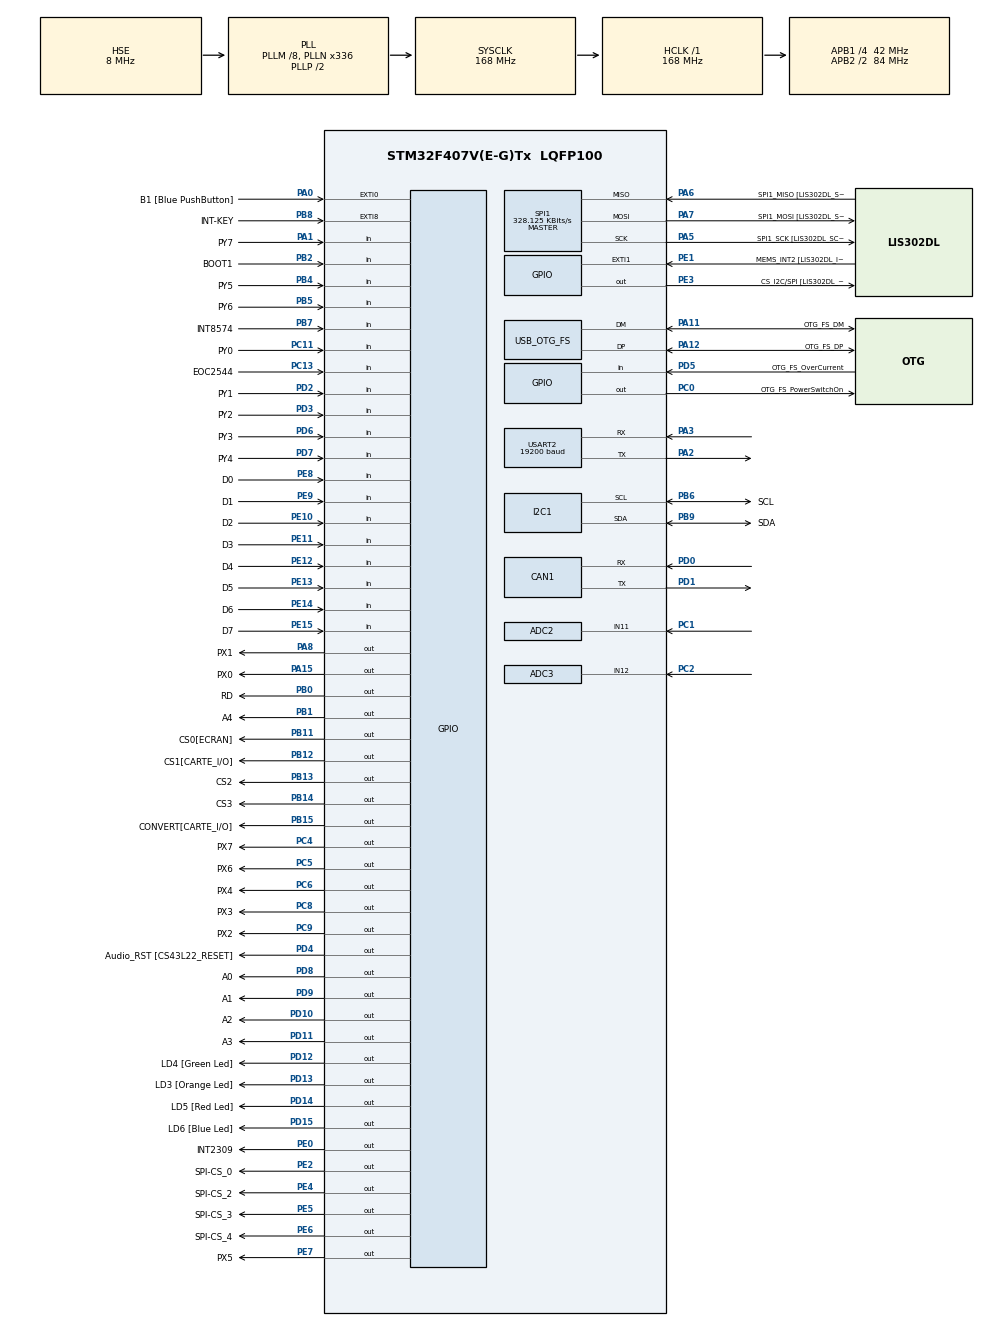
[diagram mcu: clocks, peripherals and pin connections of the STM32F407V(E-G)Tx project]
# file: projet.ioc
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ADC1.Channel-0\#ChannelRegularConversion=ADC_CHANNEL_TEMPSENSOR
ADC1.ExternalTrigConv=ADC_EXTERNALTRIGCONV_T1_CC1
ADC1.NbrOfConversionFlag=1
ADC1.Rank-0\#ChannelRegularConversion=1
ADC1.SamplingTime-0\#ChannelRegularConversion=ADC_SAMPLETIME_3CYCLES
ADC1.master=1
ADC2.Channel-0\#ChannelRegularConversion=ADC_CHANNEL_11
ADC2.ExternalTrigConv=ADC_EXTERNALTRIGCONV_T1_CC1
ADC2.NbrOfConversionFlag=1
ADC2.Rank-0\#ChannelRegularConversion=1
ADC2.SamplingTime-0\#ChannelRegularConversion=ADC_SAMPLETIME_3CYCLES
ADC3.Channel-0\#ChannelRegularConversion=ADC_CHANNEL_12
ADC3.ExternalTrigConv=ADC_EXTERNALTRIGCONV_T1_CC1
ADC3.NbrOfConversionFlag=1
ADC3.Rank-0\#ChannelRegularConversion=1
ADC3.SamplingTime-0\#ChannelRegularConversion=ADC_SAMPLETIME_3CYCLES
CAN1.CalculateTimeBit=1142
CAN1.CalculateTimeQuantum=380.95238095238096
Mcu.Family=STM32F4
Mcu.Name=STM32F407V(E-G)Tx
Mcu.Package=LQFP100
NVIC.EXTI9_5_IRQn=true\:0\:0\:false\:false\:true
NVIC.OTG_FS_IRQn=true\:0\:0\:false\:false\:true
NVIC.PriorityGroup=NVIC_PRIORITYGROUP_0
PA0-WKUP.GPIO_Label=B1 [Blue PushButton]
PA0-WKUP.GPIO_ModeDefaultEXTI=GPIO_MODE_EVT_RISING
PA0-WKUP.GPIO_PuPd=GPIO_NOPULL
PA0-WKUP.Signal=GPXTI0
PA1.GPIO_Label=PY7
PA1.Signal=GPIO_Input
PA10.GPIO_Label=OTG_FS_ID
PA10.GPIO_Mode=GPIO_MODE_AF_PP
PA10.GPIO_PuPd=GPIO_NOPULL
PA10.GPIO_Speed=GPIO_SPEED_FREQ_LOW
PA10.Signal=USB_OTG_FS_ID
PA11.GPIO_Label=OTG_FS_DM
PA11.GPIO_Mode=GPIO_MODE_AF_PP
PA11.GPIO_PuPd=GPIO_NOPULL
PA11.GPIO_Speed=GPIO_SPEED_FREQ_LOW
PA11.Mode=Device_Only
PA11.Signal=USB_OTG_FS_DM
PA12.GPIO_Label=OTG_FS_DP
PA12.GPIO_Mode=GPIO_MODE_AF_PP
PA12.GPIO_PuPd=GPIO_NOPULL
PA12.GPIO_Speed=GPIO_SPEED_FREQ_LOW
PA12.Mode=Device_Only
PA12.Signal=USB_OTG_FS_DP
PA13.GPIO_Label=SWDIO
PA13.Mode=Trace_Asynchronous_SW
PA13.Signal=SYS_JTMS-SWDIO
PA14.GPIO_Label=SWCLK
PA14.Mode=Trace_Asynchronous_SW
PA14.Signal=SYS_JTCK-SWCLK
PA15.GPIO_Label=PX0
PA15.Signal=GPIO_Output
PA2.Mode=Asynchronous
PA2.Signal=USART2_TX
PA3.Mode=Asynchronous
PA3.Signal=USART2_RX
PA4.GPIO_Label=I2S3_WS [CS43L22_LRCK]
PA4.GPIO_Mode=GPIO_MODE_AF_PP
PA4.GPIO_PuPd=GPIO_NOPULL
PA4.GPIO_Speed=GPIO_SPEED_FREQ_LOW
PA4.Signal=I2S3_WS
PA5.GPIO_Label=SPI1_SCK [LIS302DL_SCL/SPC]
PA5.GPIO_Mode=GPIO_MODE_AF_PP
PA5.GPIO_PuPd=GPIO_NOPULL
PA5.GPIO_Speed=GPIO_SPEED_FREQ_LOW
PA5.Mode=Full_Duplex_Master
PA5.Signal=SPI1_SCK
PA6.GPIO_Label=SPI1_MISO [LIS302DL_SDO]
PA6.GPIO_Mode=GPIO_MODE_AF_PP
PA6.GPIO_PuPd=GPIO_NOPULL
PA6.GPIO_Speed=GPIO_SPEED_FREQ_LOW
PA6.Mode=Full_Duplex_Master
PA6.Signal=SPI1_MISO
PA7.GPIO_Label=SPI1_MOSI [LIS302DL_SDA/SDI/SDO]
PA7.GPIO_Mode=GPIO_MODE_AF_PP
PA7.GPIO_PuPd=GPIO_NOPULL
PA7.GPIO_Speed=GPIO_SPEED_FREQ_LOW
PA7.Mode=Full_Duplex_Master
PA7.Signal=SPI1_MOSI
PA8.GPIO_Label=PX1
PA8.Signal=GPIO_Output
PA9.GPIO_Label=VBUS_FS
PA9.GPIO_Mode=GPIO_MODE_INPUT
PA9.GPIO_PuPd=GPIO_NOPULL
PA9.Signal=USB_OTG_FS_VBUS
PB0.GPIO_Label=RD
PB0.Signal=GPIO_Output
PB1.GPIO_Label=A4
PB1.Signal=GPIO_Output
PB10.GPIO_Label=CLK_IN [MP45DT02_CLK]
PB10.GPIO_Mode=GPIO_MODE_AF_PP
PB10.GPIO_PuPd=GPIO_NOPULL
PB10.GPIO_Speed=GPIO_SPEED_FREQ_LOW
PB10.Signal=I2S2_CK
PB11.GPIO_Label=CS0[ECRAN]
PB11.Signal=GPIO_Output
PB12.GPIO_Label=CS1[CARTE_I/O]
PB12.Signal=GPIO_Output
PB13.GPIO_Label=CS2
PB13.Signal=GPIO_Output
PB14.GPIO_Label=CS3
PB14.Signal=GPIO_Output
PB15.GPIO_Label=CONVERT[CARTE_I/O]
PB15.Signal=GPIO_Output
PB2.GPIO_Label=BOOT1
PB2.GPIO_Mode=GPIO_MODE_INPUT
PB2.GPIO_PuPd=GPIO_NOPULL
PB2.Signal=GPIO_Input
PB3.GPIO_Label=SWO
PB3.Mode=Trace_Asynchronous_SW
PB3.Signal=SYS_JTDO-SWO
PB4.GPIO_Label=PY5
PB4.Signal=GPIO_Input
PB5.GPIO_Label=PY6
PB5.Signal=GPIO_Input
PB6.GPIO_Label=SCL
PB6.GPIO_Mode=GPIO_MODE_AF_OD
PB6.GPIO_PuPd=GPIO_NOPULL
PB6.GPIO_Speed=GPIO_SPEED_FREQ_LOW
PB6.Mode=I2C
PB6.Signal=I2C1_SCL
PB7.GPIO_Label=INT8574
PB7.Signal=GPIO_Input
PB8.GPIO_Label=INT-KEY
PB8.Signal=GPXTI8
PB9.GPIO_Label=SDA
PB9.GPIO_Mode=GPIO_MODE_AF_OD
PB9.GPIO_PuPd=GPIO_NOPULL
PB9.GPIO_Speed=GPIO_SPEED_FREQ_LOW
PB9.Mode=I2C
PB9.Signal=I2C1_SDA
PC0.GPIO_Label=OTG_FS_PowerSwitchOn
PC0.GPIO_PuPd=GPIO_NOPULL
PC0.GPIO_Speed=GPIO_SPEED_FREQ_LOW
PC0.Signal=GPIO_Output
PC1.Signal=ADCx_IN11
PC10.GPIO_Label=I2S3_SCK [CS43L22_SCLK]
PC10.GPIO_Mode=GPIO_MODE_AF_PP
PC10.GPIO_PuPd=GPIO_NOPULL
PC10.GPIO_Speed=GPIO_SPEED_FREQ_LOW
PC10.Signal=I2S3_CK
PC11.GPIO_Label=PY0
PC11.Signal=GPIO_Input
PC12.GPIO_Label=I2S3_SD [CS43L22_SDIN]
PC12.GPIO_Mode=GPIO_MODE_AF_PP
PC12.GPIO_PuPd=GPIO_NOPULL
PC12.GPIO_Speed=GPIO_SPEED_FREQ_LOW
PC12.Signal=I2S3_SD
PC13-ANTI_TAMP.GPIO_Label=EOC2544
PC13-ANTI_TAMP.Signal=GPIO_Input
PC14-OSC32_IN.GPIO_Label=PC14-OSC32_IN
PC14-OSC32_IN.Signal=RCC_OSC32_IN
PC15-OSC32_OUT.GPIO_Label=PC15-OSC32_OUT
PC15-OSC32_OUT.Signal=RCC_OSC32_OUT
PC2.Signal=ADCx_IN12
PC3.GPIO_Label=PDM_OUT [MP45DT02_DOUT]
PC3.GPIO_Mode=GPIO_MODE_AF_PP
PC3.GPIO_PuPd=GPIO_NOPULL
PC3.GPIO_Speed=GPIO_SPEED_FREQ_LOW
PC3.Signal=I2S2_SD
PC4.GPIO_Label=PX7
PC4.Signal=GPIO_Output
PC5.GPIO_Label=PX6
PC5.Signal=GPIO_Output
PC6.GPIO_Label=PX4
PC6.Signal=GPIO_Output
PC7.GPIO_Label=I2S3_MCK [CS43L22_MCLK]
PC7.GPIO_Mode=GPIO_MODE_AF_PP
PC7.GPIO_PuPd=GPIO_NOPULL
PC7.GPIO_Speed=GPIO_SPEED_FREQ_LOW
PC7.Signal=I2S3_MCK
PC8.GPIO_Label=PX3
PC8.Signal=GPIO_Output
PC9.GPIO_Label=PX2
PC9.Signal=GPIO_Output
PD0.Mode=Master
PD0.Signal=CAN1_RX
PD1.Mode=Master
PD1.Signal=CAN1_TX
PD10.GPIO_Label=A2
PD10.Signal=GPIO_Output
PD11.GPIO_Label=A3
PD11.Signal=GPIO_Output
PD12.GPIO_Label=LD4 [Green Led]
PD12.GPIO_PuPd=GPIO_NOPULL
PD12.GPIO_Speed=GPIO_SPEED_FREQ_LOW
PD12.Signal=GPIO_Output
PD13.GPIO_Label=LD3 [Orange Led]
PD13.GPIO_PuPd=GPIO_NOPULL
PD13.GPIO_Speed=GPIO_SPEED_FREQ_LOW
PD13.Signal=GPIO_Output
PD14.GPIO_Label=LD5 [Red Led]
PD14.GPIO_PuPd=GPIO_NOPULL
PD14.GPIO_Speed=GPIO_SPEED_FREQ_LOW
PD14.Signal=GPIO_Output
PD15.GPIO_Label=LD6 [Blue Led]
PD15.GPIO_PuPd=GPIO_NOPULL
PD15.GPIO_Speed=GPIO_SPEED_FREQ_LOW
PD15.Signal=GPIO_Output
PD2.GPIO_Label=PY1
PD2.Signal=GPIO_Input
PD3.GPIO_Label=PY2
PD3.Signal=GPIO_Input
PD4.GPIO_Label=Audio_RST [CS43L22_RESET]
PD4.GPIO_PuPd=GPIO_NOPULL
PD4.GPIO_Speed=GPIO_SPEED_FREQ_LOW
PD4.Signal=GPIO_Output
PD5.GPIO_Label=OTG_FS_OverCurrent
PD5.GPIO_Mode=GPIO_MODE_INPUT
PD5.GPIO_PuPd=GPIO_NOPULL
PD5.Signal=GPIO_Input
PD6.GPIO_Label=PY3
PD6.Signal=GPIO_Input
PD7.GPIO_Label=PY4
PD7.Signal=GPIO_Input
PD8.GPIO_Label=A0
PD8.Signal=GPIO_Output
PD9.GPIO_Label=A1
PD9.Signal=GPIO_Output
PE0.GPIO_Label=INT2309
PE0.Signal=GPIO_Output
PE1.GPIO_Label=MEMS_INT2 [LIS302DL_INT2]
PE1.GPIO_ModeDefaultEXTI=GPIO_MODE_EVT_RISING
PE1.GPIO_PuPd=GPIO_NOPULL
PE1.Signal=GPXTI1
PE10.GPIO_Label=D2
PE10.Signal=GPIO_Input
PE11.GPIO_Label=D3
PE11.Signal=GPIO_Input
PE12.GPIO_Label=D4
PE12.Signal=GPIO_Input
PE13.GPIO_Label=D5
PE13.Signal=GPIO_Input
PE14.GPIO_Label=D6
PE14.Signal=GPIO_Input
PE15.GPIO_Label=D7
PE15.Signal=GPIO_Input
PE2.GPIO_Label=SPI-CS_0
PE2.Signal=GPIO_Output
PE3.GPIO_Label=CS_I2C/SPI [LIS302DL_CS_I2C/SPI]
PE3.GPIO_PuPd=GPIO_NOPULL
PE3.GPIO_Speed=GPIO_SPEED_FREQ_LOW
PE3.Signal=GPIO_Output
PE4.GPIO_Label=SPI-CS_2
PE4.Signal=GPIO_Output
PE5.GPIO_Label=SPI-CS_3
PE5.Signal=GPIO_Output
PE6.GPIO_Label=SPI-CS_4
PE6.Signal=GPIO_Output
PE7.GPIO_Label=PX5
PE7.Signal=GPIO_Output
PE8.GPIO_Label=D0
PE8.Signal=GPIO_Input
PE9.GPIO_Label=D1
PE9.Signal=GPIO_Input
PH0-OSC_IN.GPIO_Label=PH0-OSC_IN
PH0-OSC_IN.Mode=HSE-External-Oscillator
PH0-OSC_IN.Signal=RCC_OSC_IN
PH1-OSC_OUT.GPIO_Label=PH1-OSC_OUT
PH1-OSC_OUT.Mode=HSE-External-Oscillator
PH1-OSC_OUT.Signal=RCC_OSC_OUT
ProjectManager.HeapSize=0x400
ProjectManager.StackSize=0x2000
ProjectManager.TargetToolchain=EWARM
RCC.AHBFreq_Value=168000000
RCC.APB1CLKDivider=RCC_HCLK_DIV4
RCC.APB1Freq_Value=42000000
RCC.APB1TimFreq_Value=84000000
RCC.APB2CLKDivider=RCC_HCLK_DIV2
RCC.APB2Freq_Value=84000000
RCC.APB2TimFreq_Value=168000000
RCC.CortexFreq_Value=168000000
RCC.HCLKFreq_Value=168000000
RCC.HSE_VALUE=8000000
RCC.HSI_VALUE=16000000
RCC.LSE_VALUE=32768
RCC.PLLM=8
RCC.PLLN=336
RCC.PLLQ=7
RCC.SYSCLKFreq_VALUE=168000000
RCC.SYSCLKSource=RCC_SYSCLKSOURCE_PLLCLK
RCC.VCOOutputFreq_Value=336000000
SH.ADCx_IN11.0=ADC2_IN11,IN11
SH.ADCx_IN12.0=ADC3_IN12,IN12
SPI1.BaudRatePrescaler=SPI_BAUDRATEPRESCALER_256
SPI1.CalculateBaudRate=328.125 KBits/s
SPI1.Mode=SPI_MODE_MASTER
USART2.BaudRate=19200
USB_DEVICE.CLASS_NAME-CDC_FS=CDC
USB_DEVICE.CLASS_NAME_FS=CDC
USB_DEVICE.USBD_HandleTypeDef-CDC_FS=hUsbDeviceFS
USB_DEVICE.VirtualMode-CDC_FS=Cdc
USB_DEVICE.VirtualModeFS=Cdc_FS
USB_OTG_FS.VirtualMode=Device_Only
VP_ADC1_TempSens_Input.Mode=IN-TempSens
VP_USB_DEVICE_VS_USB_DEVICE_CDC_FS.Mode=CDC_FS
board=STM32F4DISCOVERY

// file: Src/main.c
/**
  ******************************************************************************
  * File Name          : main.c
  * Description        : Main program body
  ******************************************************************************
  *
  * Copyright (c) 2017 STMicroelectronics International N.V.
  * All rights reserved.
  *
  * Redistribution and use in source and binary forms, with or without
  * modification, are permitted, provided that the following conditions are met:
  *
  * 1. Redistribution of source code must retain the above copyright notice,
  *    this list of conditions and the following disclaimer.
  * 2. Redistributions in binary form must reproduce the above copyright notice,
  *    this list of conditions and the following disclaimer in the documentation
  *    and/or other materials provided with the distribution.
  * 3. Neither the name of STMicroelectronics nor the names of other
  *    contributors to this software may be used to endorse or promote products
  *    derived from this software without specific written permission.
  * 4. This software, including modifications and/or derivative works of this
  *    software, must execute solely and exclusively on microcontroller or
  *    microprocessor devices manufactured by or for STMicroelectronics.
  * 5. Redistribution and use of this software other than as permitted under
  *    this license is void and will automatically terminate your rights under
  *    this license.
  *
  * THIS SOFTWARE IS PROVIDED BY STMICROELECTRONICS AND CONTRIBUTORS "AS IS"
  * AND ANY EXPRESS, IMPLIED OR STATUTORY WARRANTIES, INCLUDING, BUT NOT
  * LIMITED TO, THE IMPLIED WARRANTIES OF MERCHANTABILITY, FITNESS FOR A
  * PARTICULAR PURPOSE AND NON-INFRINGEMENT OF THIRD PARTY INTELLECTUAL PROPERTY
  * RIGHTS ARE DISCLAIMED TO THE FULLEST EXTENT PERMITTED BY LAW. IN NO EVENT
  * SHALL STMICROELECTRONICS OR CONTRIBUTORS BE LIABLE FOR ANY DIRECT, INDIRECT,
  * INCIDENTAL, SPECIAL, EXEMPLARY, OR CONSEQUENTIAL DAMAGES (INCLUDING, BUT NOT
  * LIMITED TO, PROCUREMENT OF SUBSTITUTE GOODS OR SERVICES; LOSS OF USE, DATA,
  * OR PROFITS; OR BUSINESS INTERRUPTION) HOWEVER CAUSED AND ON ANY THEORY OF
  * LIABILITY, WHETHER IN CONTRACT, STRICT LIABILITY, OR TORT (INCLUDING
  * NEGLIGENCE OR OTHERWISE) ARISING IN ANY WAY OUT OF THE USE OF THIS SOFTWARE,
  * EVEN IF ADVISED OF THE POSSIBILITY OF SUCH DAMAGE.
  *
  ******************************************************************************
  */
#include "main.h"
#include "stm32f4xx_hal.h"
#include "usb_device.h"

/* USER CODE BEGIN Includes */
#include "LIS3DSH.h"
#include "IO_BUS.h"
#include "GLcd.h"
#include "ST.h"
#include "Vehicule.h"
/* USER CODE END Includes */

ADC_HandleTypeDef hadc1;
ADC_HandleTypeDef hadc2;
ADC_HandleTypeDef hadc3;

CAN_HandleTypeDef hcan1;

I2C_HandleTypeDef hi2c1;

SPI_HandleTypeDef hspi1;

UART_HandleTypeDef huart2;

/* USER CODE BEGIN PV */
/* Private variables ---------------------------------------------------------*/

/* USER CODE END PV */

void SystemClock_Config(void);
void Error_Handler(void);
static void MX_GPIO_Init(void);
static void MX_ADC1_Init(void);
static void MX_ADC2_Init(void);
static void MX_ADC3_Init(void);
static void MX_CAN1_Init(void);
static void MX_I2C1_Init(void);
static void MX_SPI1_Init(void);
static void MX_USART2_UART_Init(void);

/* USER CODE BEGIN PFP */
/* Private function prototypes -----------------------------------------------*/

/* USER CODE END PFP */

/* USER CODE BEGIN 0 */
 uint8_t ucKey = 0x20;
/* USER CODE END 0 */

int main(void)
{

  /* USER CODE BEGIN 1 */

  uint8_t ucCode[16] = {'1','2','3','A',
                        '4','5','6','B',
                        '7','8','9','C',
                        '*','0','#','D'};

  uint8_t ucTrans[20] = {'0','0','0',0,0,' ',' ',' ',' ',' ',
                         ' ',' ',' ',' ',' ',' ',' ',' ',' ',' '};
                        // Trame Clavier
 int iRoue[4];

 unsigned char ucTrameRoue[20] = {0,0,0,0,0,0,0,0,0,0,
                                  0,0,0,0,0,0,0,0,0,0};
  // 12 (4*3) pour les roues
  // 2 pour checksum

 unsigned char ucTrameDebug[20] = {'A','V','G','A','V','D', 'A','R','G',
                                   'A','R','D'};

  unsigned char ucTableauFloat[20] = {' ',' ',' ',' ',' ',' ',' ',' ',' ',' ',
  ' ',' ',' ',' ',' ',' ',' ',' ',' ',' '};

  uint8_t ucCtrlTele = 0;  // Controle inclinometre ou clavier. Clavier = 0
                           // Inclinometre = 1.
                           // Suiveur = 2
                           // Capteur = 3.
                           // Mode clavier au demarrage.

  unsigned char *ucpTrans;
  int *ipRoue;
  unsigned char *ucpTrameRoue;
  float fXData;
  float fYData;

/* int iTest;
  unsigned char iTest1;
  unsigned char iTest2;
    unsigned char iTest3;
    unsigned char iTest4;
  unsigned char ucPCF;*/

  /* USER CODE END 1 */

  /* MCU Configuration----------------------------------------------------------*/

  /* Reset of all peripherals, Initializes the Flash interface and the Systick. */
  HAL_Init();

  /* Configure the system clock */
  SystemClock_Config();

  /* Initialize all configured peripherals */
  MX_GPIO_Init();
  MX_ADC1_Init();
  MX_ADC2_Init();
  MX_ADC3_Init();
  MX_CAN1_Init();
  MX_I2C1_Init();
  MX_SPI1_Init();
  MX_USART2_UART_Init();
  MX_USB_DEVICE_Init();

  /* USER CODE BEGIN 2 */
  vLIS3DSHEcrire(LIS3DSH_Reg_Ctrl_4, 0x63);
  vLIS3DSHEcrire(LIS3DSH_Reg_Ctrl_5, 0xD8);
  vInitGLcd();
  vClearGLcd(0x00);
  ucpTrans = &ucTrans[0];
  ipRoue = &iRoue[0];
  ucpTrameRoue = &ucTrameRoue[0];

  /* USER CODE END 2 */

  /* Infinite loop */
  /* USER CODE BEGIN WHILE */
  while (1)
  {

    //clavier I2C
    if(ucKey != 0x20)                                 // Touche rentrer?
    {
      switch (ucCode[ucKey])
      {
      case '1':                                       // Rien
        vPutCharGLcd('1',1,1,5);
        ucTrans[0] = '0';
        ucTrans[1] = '0';
        ucTrans[2] = '0';
        ucTrans[3] = 0;                               // Checksum
        ucTrans[4] = 0;                               // Checksum
        vChecksum(ucpTrans);
        vPutStringGLcd(ucTrans, 0, 5);
        break;

      case '2':                                        // Avant
        vPutCharGLcd('2',1,1,5);
        ucTrans[0] = 'F';
        ucTrans[1] = '0';
        ucTrans[2] = '0';
        ucTrans[3] = 0;                               // Checksum
        ucTrans[4] = 0;                               // Checksum
        vChecksum(ucpTrans);
        vPutStringGLcd(ucTrans, 0, 5);
        break;

      case '3':                                       // Rien
        vPutCharGLcd('3',1,1,5);
        ucTrans[0] = '0';
        ucTrans[1] = '0';
        ucTrans[2] = '0';
        ucTrans[3] = 0;                               // Checksum
        ucTrans[4] = 0;                               // Checksum
        vChecksum(ucpTrans);
        vPutStringGLcd(ucTrans, 0, 5);
        break;

      case 'A':                                       // Suiveur
        vPutCharGLcd('A',1,1,5);
        ucTrans[0] = 'A';
        ucTrans[1] = '0';
        ucTrans[2] = '0';
        ucTrans[3] = 0;                               // Checksum
        ucTrans[4] = 0;                               // Checksum
        vChecksum(ucpTrans);
        vPutStringGLcd(ucTrans, 0, 5);
        HAL_UART_Transmit(&huart2, ucpTrans, 14, 100);
        ucCtrlTele = 2;
        break;

      case '4':                                       // Gauche
        vPutCharGLcd('4',1,1,5);
        ucTrans[0] = 'G';
        ucTrans[1] = '0';
        ucTrans[2] = '0';
        ucTrans[3] = 0;                               // Checksum
        ucTrans[4] = 0;                               // Checksum
        vChecksum(ucpTrans);
        vPutStringGLcd(ucTrans, 0, 5);
        break;

      case '5':                                       // Stop
        vPutCharGLcd('5',1,1,5);
        ucTrans[0] = 'S';
        ucTrans[1] = '0';
        ucTrans[2] = '0';
        ucTrans[3] = 0;                               // Checksum
        ucTrans[4] = 0;                               // Checksum
        vChecksum(ucpTrans);
        vPutStringGLcd(ucTrans, 0, 5);
        break;

      case '6':                                       // Droite
        vPutCharGLcd('6',1,1,5);
        ucTrans[0] = 'D';
        ucTrans[1] = '0';
        ucTrans[2] = '0';
        ucTrans[3] = 0;                               // Checksum
        ucTrans[4] = 0;                               // Checksum
        vChecksum(ucpTrans);
        vPutStringGLcd(ucTrans, 0, 5);
        break;

      case 'B':                                       // Clavier
        vPutCharGLcd('B',1,1,5);
        ucTrans[0] = 'M';
        ucTrans[1] = '0';
        ucTrans[2] = '0';
        ucTrans[3] = 0;                               // Checksum
        ucTrans[4] = 0;                               // Checksum
        vChecksum(ucpTrans);
        vPutStringGLcd(ucTrans, 0, 5);
        ucCtrlTele = 0;
        break;

      case '7':                                       // Rien
        vPutCharGLcd('7',1,1,5);
        ucTrans[0] = '0';
        ucTrans[1] = '0';
        ucTrans[2] = '0';
        ucTrans[3] = 0;                               // Checksum
        ucTrans[4] = 0;                               // Checksum
        vChecksum(ucpTrans);
        vPutStringGLcd(ucTrans, 0, 5);
        break;

      case '8':                                       // Arriere
        vPutCharGLcd('8',1,1,5);
        ucTrans[0] = 'R';
        ucTrans[1] = '0';
        ucTrans[2] = '0';
        ucTrans[3] = 0;                               // Checksum
        ucTrans[4] = 0;                               // Checksum
        vChecksum(ucpTrans);
        vPutStringGLcd(ucTrans, 0, 5);
        break;

      case '9':                                       // Inclinometre
        vPutCharGLcd('9',1,1,5);
        ucTrans[0] = 'I';
        ucTrans[1] = '0';
        ucTrans[2] = '0';
        ucTrans[3] = 0;                               // Checksum
        ucTrans[4] = 0;                               // Checksum
        vChecksum(ucpTrans);
        vPutStringGLcd(ucTrans, 0, 5);
        HAL_UART_Transmit(&huart2, ucpTrans, 14, 100);
        ucCtrlTele = 1;
        break;

      case 'C':                                       // Capteur
        vPutCharGLcd('C',1,1,5);
        ucTrans[0] = 'E';
        ucTrans[1] = '0';
        ucTrans[2] = '0';
        ucTrans[3] = 0;                               // Checksum
        ucTrans[4] = 0;                               // Checksum
        vChecksum(ucpTrans);
        vPutStringGLcd(ucTrans, 0, 5);
        HAL_UART_Transmit(&huart2, ucpTrans, 14, 100);
        ucCtrlTele = 2;
        break;

      case '*':                                       // Vitesse 1
        vPutCharGLcd('*',1,1,5);
        ucTrans[0] = 'V';
        ucTrans[1] = '1';
        ucTrans[2] = '9';
        ucTrans[3] = 0;                               // Checksum
        ucTrans[4] = 0;                               // Checksum
        vChecksum(ucpTrans);
        vPutStringGLcd(ucTrans, 0, 5);
        HAL_UART_Transmit(&huart2, ucpTrans, 14, 100);
        break;

      case '0':                                       // Vitesse 2
        vPutCharGLcd('0',1,1,5);
        ucTrans[0] = 'V';
        ucTrans[1] = '3';
        ucTrans[2] = '2';
        ucTrans[3] = 0;                               // Checksum
        ucTrans[4] = 0;                               // Checksum
        vChecksum(ucpTrans);
        vPutStringGLcd(ucTrans, 0, 5);
        HAL_UART_Transmit(&huart2, ucpTrans, 14, 100);
        break;

      case '#':                                       // Vitesse 3
        vPutCharGLcd('#',1,1,5);
        ucTrans[0] = 'V';
        ucTrans[1] = '4';
        ucTrans[2] = 'B';
        ucTrans[3] = 0;                               // Checksum
        ucTrans[4] = 0;                               // Checksum
        vChecksum(ucpTrans);
        vPutStringGLcd(ucTrans, 0, 5);
        HAL_UART_Transmit(&huart2, ucpTrans, 14, 100);
        break;

      case 'D':                                       // Vitesse 4
        vPutCharGLcd('D',1,1,5);
        ucTrans[0] = 'V';
        ucTrans[1] = '6';
        ucTrans[2] = '4';
        ucTrans[3] = 0;                               // Checksum
        ucTrans[4] = 0;                               // Checksum
        vChecksum(ucpTrans);
        vPutStringGLcd(ucTrans, 0, 5);
        HAL_UART_Transmit(&huart2, ucpTrans, 14, 100);
        break;
      }

     if(ucCtrlTele == 0)
      {
        HAL_UART_Transmit(&huart2, ucpTrans, 14, 100);
      }

      ucKey = 0x20;
      ucpTrans = &ucTrans[0];
    }    //fin if uckey

    if(ucCtrlTele == 1) // Inclinometre
    {
      fXData = fLIS3DSHLireSortieX(LIS3DSH_Sense_8g); // Lecture axe des x
      sprintf(ucTableauFloat, "%+2.2f",fXData);
      vPutStringGLcd(ucTableauFloat,2,5);
      vPutCharGLcd('X',2,5,5);

      fYData = fLIS3DSHLireSortieY(LIS3DSH_Sense_8g); // lecture axe des y
      sprintf(ucTableauFloat, "%+2.2f",fYData);
      vPutStringGLcd(ucTableauFloat,3,5);
      vPutCharGLcd('Y',3,5,5);

      if((fXData <= 0.25) && (fXData >= -0.25))       // Threshold min
      {
        fXData = 0;
      }

      if((fYData <= 0.25) && (fYData >= -0.25))       // Threshold min
      {
        fYData = 0;
      }

      if(fXData > 0.75)   // Threshold max
      {
        fXData = 0.75;
      }

      if(fXData < -0.75)  // Threshold max
      {
        fXData = -0.75;
      }

      if(fYData > 0.75)   // Threshold max
      {
        fYData = 0.75;
      }

      if(fYData < -0.75)  // Threshold max
      {
        fYData = -0.75;
      }

      fYData = fYData * (-1);

      if((fXData == 0) || (fYData == 0))       // Lineaire
      {
        if((fXData == 0) && (fYData > 0.25))   // Avant
        {
          iRoue[0] = iConVit(fYData);          // AVG
          iRoue[1] = iConVit(fYData);          // AVD
          iRoue[2] = iConVit(fYData);          // ARG
          iRoue[3] = iConVit(fYData);          // ARD
        }

        if((fXData == 0) && (fYData < -0.25))  // Arriиre
        {
          iRoue[0] = iConVit(fYData);          // AVG
          iRoue[1] = iConVit(fYData);          // AVD
          iRoue[2] = iConVit(fYData);          // ARG
          iRoue[3] = iConVit(fYData);          // ARD
        }

        if((fXData > 0.25) && (fYData == 0))   // Droite
        {
          iRoue[0] = iConVit(fXData);          // AVG
          iRoue[1] = iConVit(-fXData);         // AVD
          iRoue[2] = iConVit(fXData);          // ARG
          iRoue[3] = iConVit(-fXData);         // ARD
        }

        if((fXData < -0.25) && (fYData == 0))  // Gauche
        {
          iRoue[0] = iConVit(fXData);          // AVG
          iRoue[1] = iConVit(-fXData);         // AVD
          iRoue[2] = iConVit(fXData);          // ARG
          iRoue[3] = iConVit(-fXData);         // ARD
        }

        if((fXData == 0) && (fYData == 0))     // Stop
        {
          iRoue[0] = 0x200;                    // AVG
          iRoue[1] = 0x200;                    // AVD
          iRoue[2] = 0x200;                    // ARG
          iRoue[3] = 0x200;                    // ARD
        }

      }
      else                                     // Diagonale
      {
        if((fXData < 0) && (fYData > 0))       // Gauche Avant
        {
          iRoue[0] = iConVit(fYData) - iConX(fXData); // AVG
          iRoue[1] = iConVit(fYData);                 // AVD
          iRoue[2] = iConVit(fYData) - iConX(fXData); // ARG
          iRoue[3] = iConVit(fYData);                 // ARD
        }
        if((fXData > 0) && (fYData > 0))   // Droit Avant
        {
          iRoue[0] = iConVit(fYData);                 // AVG
          iRoue[1] = iConVit(fYData) - iConX(fXData); // AVD
          iRoue[2] = iConVit(fYData);                 // ARG
          iRoue[3] = iConVit(fYData) - iConX(fXData); // ARD
        }
        if((fXData < 0) && (fYData < 0))   // Gauche Arriere
        {
          iRoue[0] = iConVit(fYData);                 // AVG
          iRoue[1] = iConVit(fYData) + iConX(fXData); // AVD
          iRoue[2] = iConVit(fYData);                 // ARG
          iRoue[3] = iConVit(fYData) + iConX(fXData); // ARD
        }
        if((fXData > 0) && (fYData < 0))   // Droit Arriere
        {
          iRoue[0] = iConVit(fYData) + iConX(fXData); // AVG
          iRoue[1] = iConVit(fYData);                 // AVD
          iRoue[2] = iConVit(fYData) + iConX(fXData); // ARG
          iRoue[3] = iConVit(fYData);                 // ARD
        }

      }

      vIntToASCII(ipRoue,ucpTrameRoue);
      ucTrameRoue[12] = 0;                // Checksum
      ucTrameRoue[13] = 0;                // CheckSum
      vChecksum(ucpTrameRoue);
      HAL_UART_Transmit(&huart2, ucpTrameRoue, 14, 100);
      vPutStringGLcd(ucTrameRoue,4,5);
      vPutStringGLcd(ucTrameDebug,5,5);
     } //fin if inclinometre

    //Test MAX1236
   /*
    iTest = i1236ReadChanel();
    iTest1 = ((iTest & 0xF000) >> 12) + 0x30;
    iTest2 = ((iTest & 0x0F00) >> 8) + 0x30;
    iTest3 = ((iTest & 0x00F0) >> 4)+ 0x30;
    iTest4 = (iTest & 0x000F)+ 0x30;
    vPutCharGLcd(iTest1,1,0,5);
    vPutCharGLcd(iTest2,1,1,5);
    vPutCharGLcd(iTest3,1,2,5);
    vPutCharGLcd(iTest4,1,3,5);

    //Test Dac
  //  v6574WriteInt('0', 0xFfff);

    //Test PCF
    //ucPCF = (uc8574ReadByte() + 0x30);
   ///vPutCharGLcd(ucPCF,1,0,5);
   // v8574WriteByte(0x35);
    */

  /* USER CODE END WHILE */

  }

}

/** System Clock Configuration
*/
void SystemClock_Config(void)
{

  RCC_OscInitTypeDef RCC_OscInitStruct;
  RCC_ClkInitTypeDef RCC_ClkInitStruct;

    /**Configure the main internal regulator output voltage
    */
  __HAL_RCC_PWR_CLK_ENABLE();

  __HAL_PWR_VOLTAGESCALING_CONFIG(PWR_REGULATOR_VOLTAGE_SCALE1);

    /**Initializes the CPU, AHB and APB busses clocks
    */
  RCC_OscInitStruct.OscillatorType = RCC_OSCILLATORTYPE_HSE;
  RCC_OscInitStruct.HSEState = RCC_HSE_ON;
  RCC_OscInitStruct.PLL.PLLState = RCC_PLL_ON;
  RCC_OscInitStruct.PLL.PLLSource = RCC_PLLSOURCE_HSE;
  RCC_OscInitStruct.PLL.PLLM = 8;
  RCC_OscInitStruct.PLL.PLLN = 336;
  RCC_OscInitStruct.PLL.PLLP = RCC_PLLP_DIV2;
  RCC_OscInitStruct.PLL.PLLQ = 7;
  if (HAL_RCC_OscConfig(&RCC_OscInitStruct) != HAL_OK)
  {
    Error_Handler();
  }

    /**Initializes the CPU, AHB and APB busses clocks
    */
  RCC_ClkInitStruct.ClockType = RCC_CLOCKTYPE_HCLK|RCC_CLOCKTYPE_SYSCLK
                              |RCC_CLOCKTYPE_PCLK1|RCC_CLOCKTYPE_PCLK2;
  RCC_ClkInitStruct.SYSCLKSource = RCC_SYSCLKSOURCE_PLLCLK;
  RCC_ClkInitStruct.AHBCLKDivider = RCC_SYSCLK_DIV1;
  RCC_ClkInitStruct.APB1CLKDivider = RCC_HCLK_DIV4;
  RCC_ClkInitStruct.APB2CLKDivider = RCC_HCLK_DIV2;

  if (HAL_RCC_ClockConfig(&RCC_ClkInitStruct, FLASH_LATENCY_5) != HAL_OK)
  {
    Error_Handler();
  }

    /**Configure the Systick interrupt time
    */
  HAL_SYSTICK_Config(HAL_RCC_GetHCLKFreq()/1000);

    /**Configure the Systick
    */
  HAL_SYSTICK_CLKSourceConfig(SYSTICK_CLKSOURCE_HCLK);

  /* SysTick_IRQn interrupt configuration */
  HAL_NVIC_SetPriority(SysTick_IRQn, 0, 0);
}

/* ADC1 init function */
static void MX_ADC1_Init(void)
{

  ADC_ChannelConfTypeDef sConfig;

    /**Configure the global features of the ADC (Clock, Resolution, Data Alignment and number of conversion)
    */
  hadc1.Instance = ADC1;
  hadc1.Init.ClockPrescaler = ADC_CLOCK_SYNC_PCLK_DIV4;
  hadc1.Init.Resolution = ADC_RESOLUTION_12B;
  hadc1.Init.ScanConvMode = DISABLE;
  hadc1.Init.ContinuousConvMode = DISABLE;
  hadc1.Init.DiscontinuousConvMode = DISABLE;
  hadc1.Init.ExternalTrigConvEdge = ADC_EXTERNALTRIGCONVEDGE_RISING;
  hadc1.Init.ExternalTrigConv = ADC_EXTERNALTRIGCONV_T1_CC1;
  hadc1.Init.DataAlign = ADC_DATAALIGN_RIGHT;
  hadc1.Init.NbrOfConversion = 1;
  hadc1.Init.DMAContinuousRequests = DISABLE;
  hadc1.Init.EOCSelection = ADC_EOC_SINGLE_CONV;
  if (HAL_ADC_Init(&hadc1) != HAL_OK)
  {
    Error_Handler();
  }

    /**Configure for the selected ADC regular channel its corresponding rank in the sequencer and its sample time.
    */
  sConfig.Channel = ADC_CHANNEL_TEMPSENSOR;
  sConfig.Rank = 1;
  sConfig.SamplingTime = ADC_SAMPLETIME_3CYCLES;
  if (HAL_ADC_ConfigChannel(&hadc1, &sConfig) != HAL_OK)
  {
    Error_Handler();
  }

}

/* ADC2 init function */
static void MX_ADC2_Init(void)
{

  ADC_ChannelConfTypeDef sConfig;

    /**Configure the global features of the ADC (Clock, Resolution, Data Alignment and number of conversion)
    */
  hadc2.Instance = ADC2;
  hadc2.Init.ClockPrescaler = ADC_CLOCK_SYNC_PCLK_DIV4;
  hadc2.Init.Resolution = ADC_RESOLUTION_12B;
  hadc2.Init.ScanConvMode = DISABLE;
  hadc2.Init.ContinuousConvMode = DISABLE;
  hadc2.Init.DiscontinuousConvMode = DISABLE;
  hadc2.Init.ExternalTrigConvEdge = ADC_EXTERNALTRIGCONVEDGE_RISING;
  hadc2.Init.ExternalTrigConv = ADC_EXTERNALTRIGCONV_T1_CC1;
  hadc2.Init.DataAlign = ADC_DATAALIGN_RIGHT;
  hadc2.Init.NbrOfConversion = 1;
  hadc2.Init.DMAContinuousRequests = DISABLE;
  hadc2.Init.EOCSelection = ADC_EOC_SINGLE_CONV;
  if (HAL_ADC_Init(&hadc2) != HAL_OK)
  {
    Error_Handler();
  }

    /**Configure for the selected ADC regular channel its corresponding rank in the sequencer and its sample time.
    */
  sConfig.Channel = ADC_CHANNEL_11;
  sConfig.Rank = 1;
  sConfig.SamplingTime = ADC_SAMPLETIME_3CYCLES;
  if (HAL_ADC_ConfigChannel(&hadc2, &sConfig) != HAL_OK)
  {
    Error_Handler();
  }

}

/* ADC3 init function */
static void MX_ADC3_Init(void)
{

  ADC_ChannelConfTypeDef sConfig;

    /**Configure the global features of the ADC (Clock, Resolution, Data Alignment and number of conversion)
    */
  hadc3.Instance = ADC3;
  hadc3.Init.ClockPrescaler = ADC_CLOCK_SYNC_PCLK_DIV4;
  hadc3.Init.Resolution = ADC_RESOLUTION_12B;
  hadc3.Init.ScanConvMode = DISABLE;
  hadc3.Init.ContinuousConvMode = DISABLE;
  hadc3.Init.DiscontinuousConvMode = DISABLE;
  hadc3.Init.ExternalTrigConvEdge = ADC_EXTERNALTRIGCONVEDGE_RISING;
  hadc3.Init.ExternalTrigConv = ADC_EXTERNALTRIGCONV_T1_CC1;
  hadc3.Init.DataAlign = ADC_DATAALIGN_RIGHT;
  hadc3.Init.NbrOfConversion = 1;
  hadc3.Init.DMAContinuousRequests = DISABLE;
  hadc3.Init.EOCSelection = ADC_EOC_SINGLE_CONV;
  if (HAL_ADC_Init(&hadc3) != HAL_OK)
  {
    Error_Handler();
  }

    /**Configure for the selected ADC regular channel its corresponding rank in the sequencer and its sample time.
    */
  sConfig.Channel = ADC_CHANNEL_12;
  sConfig.Rank = 1;
  sConfig.SamplingTime = ADC_SAMPLETIME_3CYCLES;
  if (HAL_ADC_ConfigChannel(&hadc3, &sConfig) != HAL_OK)
  {
    Error_Handler();
  }

}

/* CAN1 init function */
static void MX_CAN1_Init(void)
{

  hcan1.Instance = CAN1;
  hcan1.Init.Prescaler = 16;
  hcan1.Init.Mode = CAN_MODE_NORMAL;
  hcan1.Init.SJW = CAN_SJW_1TQ;
  hcan1.Init.BS1 = CAN_BS1_1TQ;
  hcan1.Init.BS2 = CAN_BS2_1TQ;
  hcan1.Init.TTCM = DISABLE;
  hcan1.Init.ABOM = DISABLE;
  hcan1.Init.AWUM = DISABLE;
  hcan1.Init.NART = DISABLE;
  hcan1.Init.RFLM = DISABLE;
  hcan1.Init.TXFP = DISABLE;
  if (HAL_CAN_Init(&hcan1) != HAL_OK)
  {
    Error_Handler();
  }

}

/* I2C1 init function */
static void MX_I2C1_Init(void)
{

  hi2c1.Instance = I2C1;
  hi2c1.Init.ClockSpeed = 100000;
  hi2c1.Init.DutyCycle = I2C_DUTYCYCLE_2;
  hi2c1.Init.OwnAddress1 = 0;
  hi2c1.Init.AddressingMode = I2C_ADDRESSINGMODE_7BIT;
  hi2c1.Init.DualAddressMode = I2C_DUALADDRESS_DISABLE;
  hi2c1.Init.OwnAddress2 = 0;
  hi2c1.Init.GeneralCallMode = I2C_GENERALCALL_DISABLE;
  hi2c1.Init.NoStretchMode = I2C_NOSTRETCH_DISABLE;
  if (HAL_I2C_Init(&hi2c1) != HAL_OK)
  {
    Error_Handler();
  }

}

/* SPI1 init function */
static void MX_SPI1_Init(void)
{

  hspi1.Instance = SPI1;
  hspi1.Init.Mode = SPI_MODE_MASTER;
  hspi1.Init.Direction = SPI_DIRECTION_2LINES;
  hspi1.Init.DataSize = SPI_DATASIZE_8BIT;
  hspi1.Init.CLKPolarity = SPI_POLARITY_LOW;
  hspi1.Init.CLKPhase = SPI_PHASE_1EDGE;
  hspi1.Init.NSS = SPI_NSS_SOFT;
  hspi1.Init.BaudRatePrescaler = SPI_BAUDRATEPRESCALER_256;
  hspi1.Init.FirstBit = SPI_FIRSTBIT_MSB;
  hspi1.Init.TIMode = SPI_TIMODE_DISABLE;
  hspi1.Init.CRCCalculation = SPI_CRCCALCULATION_DISABLE;
  hspi1.Init.CRCPolynomial = 10;
  if (HAL_SPI_Init(&hspi1) != HAL_OK)
  {
    Error_Handler();
  }

}

/* USART2 init function */
static void MX_USART2_UART_Init(void)
{

  huart2.Instance = USART2;
  huart2.Init.BaudRate = 19200;
  huart2.Init.WordLength = UART_WORDLENGTH_8B;
  huart2.Init.StopBits = UART_STOPBITS_1;
  huart2.Init.Parity = UART_PARITY_NONE;
  huart2.Init.Mode = UART_MODE_TX_RX;
  huart2.Init.HwFlowCtl = UART_HWCONTROL_NONE;
  huart2.Init.OverSampling = UART_OVERSAMPLING_16;
  if (HAL_UART_Init(&huart2) != HAL_OK)
  {
    Error_Handler();
  }

}

/** Configure pins as
        * Analog
        * Input
        * Output
        * EVENT_OUT
        * EXTI
     PC3   ------> I2S2_SD
     PA4   ------> I2S3_WS
     PB10   ------> I2S2_CK
     PC7   ------> I2S3_MCK
     PC10   ------> I2S3_CK
     PC12   ------> I2S3_SD
*/
static void MX_GPIO_Init(void)
{

  GPIO_InitTypeDef GPIO_InitStruct;

  /* GPIO Ports Clock Enable */
  __HAL_RCC_GPIOE_CLK_ENABLE();
  __HAL_RCC_GPIOC_CLK_ENABLE();
  __HAL_RCC_GPIOH_CLK_ENABLE();
  __HAL_RCC_GPIOA_CLK_ENABLE();
  __HAL_RCC_GPIOB_CLK_ENABLE();
  __HAL_RCC_GPIOD_CLK_ENABLE();

  /*Configure GPIO pin Output Level */
  HAL_GPIO_WritePin(GPIOE, SPI_CS_0_Pin|CS_I2C_SPI_Pin|SPI_CS_2_Pin|SPI_CS_3_Pin
                          |SPI_CS_4_Pin|PX5_Pin|INT2309_Pin, GPIO_PIN_RESET);

  /*Configure GPIO pin Output Level */
  HAL_GPIO_WritePin(GPIOC, OTG_FS_PowerSwitchOn_Pin|PX7_Pin|PX6_Pin|PX4_Pin
                          |PX3_Pin|PX2_Pin, GPIO_PIN_RESET);

  /*Configure GPIO pin Output Level */
  HAL_GPIO_WritePin(GPIOB, RD_Pin|A4_Pin|CS0_Pin|CS1_Pin
                          |CS2_Pin|CS3_Pin|CONVERT_Pin, GPIO_PIN_RESET);

  /*Configure GPIO pin Output Level */
  HAL_GPIO_WritePin(GPIOD, A0_Pin|A1_Pin|A2_Pin|A3_Pin
                          |LD4_Pin|LD3_Pin|LD5_Pin|LD6_Pin
                          |Audio_RST_Pin, GPIO_PIN_RESET);

  /*Configure GPIO pin Output Level */
  HAL_GPIO_WritePin(GPIOA, PX1_Pin|PX0_Pin, GPIO_PIN_RESET);

  /*Configure GPIO pins : SPI_CS_0_Pin CS_I2C_SPI_Pin SPI_CS_2_Pin SPI_CS_3_Pin
                           SPI_CS_4_Pin PX5_Pin INT2309_Pin */
  GPIO_InitStruct.Pin = SPI_CS_0_Pin|CS_I2C_SPI_Pin|SPI_CS_2_Pin|SPI_CS_3_Pin
                          |SPI_CS_4_Pin|PX5_Pin|INT2309_Pin;
  GPIO_InitStruct.Mode = GPIO_MODE_OUTPUT_PP;
  GPIO_InitStruct.Pull = GPIO_NOPULL;
  GPIO_InitStruct.Speed = GPIO_SPEED_FREQ_LOW;
  HAL_GPIO_Init(GPIOE, &GPIO_InitStruct);

  /*Configure GPIO pins : EOC2544_Pin PY0_Pin */
  GPIO_InitStruct.Pin = EOC2544_Pin|PY0_Pin;
  GPIO_InitStruct.Mode = GPIO_MODE_INPUT;
  GPIO_InitStruct.Pull = GPIO_NOPULL;
  HAL_GPIO_Init(GPIOC, &GPIO_InitStruct);

  /*Configure GPIO pins : OTG_FS_PowerSwitchOn_Pin PX7_Pin PX6_Pin PX4_Pin
                           PX3_Pin PX2_Pin */
  GPIO_InitStruct.Pin = OTG_FS_PowerSwitchOn_Pin|PX7_Pin|PX6_Pin|PX4_Pin
                          |PX3_Pin|PX2_Pin;
  GPIO_InitStruct.Mode = GPIO_MODE_OUTPUT_PP;
  GPIO_InitStruct.Pull = GPIO_NOPULL;
  GPIO_InitStruct.Speed = GPIO_SPEED_FREQ_LOW;
  HAL_GPIO_Init(GPIOC, &GPIO_InitStruct);

  /*Configure GPIO pin : PDM_OUT_Pin */
  GPIO_InitStruct.Pin = PDM_OUT_Pin;
  GPIO_InitStruct.Mode = GPIO_MODE_AF_PP;
  GPIO_InitStruct.Pull = GPIO_NOPULL;
  GPIO_InitStruct.Speed = GPIO_SPEED_FREQ_LOW;
  GPIO_InitStruct.Alternate = GPIO_AF5_SPI2;
  HAL_GPIO_Init(PDM_OUT_GPIO_Port, &GPIO_InitStruct);

  /*Configure GPIO pin : B1_Pin */
  GPIO_InitStruct.Pin = B1_Pin;
  GPIO_InitStruct.Mode = GPIO_MODE_EVT_RISING;
  GPIO_InitStruct.Pull = GPIO_NOPULL;
  HAL_GPIO_Init(B1_GPIO_Port, &GPIO_InitStruct);

  /*Configure GPIO pin : PY7_Pin */
  GPIO_InitStruct.Pin = PY7_Pin;
  GPIO_InitStruct.Mode = GPIO_MODE_INPUT;
  GPIO_InitStruct.Pull = GPIO_NOPULL;
  HAL_GPIO_Init(PY7_GPIO_Port, &GPIO_InitStruct);

  /*Configure GPIO pin : I2S3_WS_Pin */
  GPIO_InitStruct.Pin = I2S3_WS_Pin;
  GPIO_InitStruct.Mode = GPIO_MODE_AF_PP;
  GPIO_InitStruct.Pull = GPIO_NOPULL;
  GPIO_InitStruct.Speed = GPIO_SPEED_FREQ_LOW;
  GPIO_InitStruct.Alternate = GPIO_AF6_SPI3;
  HAL_GPIO_Init(I2S3_WS_GPIO_Port, &GPIO_InitStruct);

  /*Configure GPIO pins : RD_Pin A4_Pin CS0_Pin CS1_Pin
                           CS2_Pin CS3_Pin CONVERT_Pin */
  GPIO_InitStruct.Pin = RD_Pin|A4_Pin|CS0_Pin|CS1_Pin
                          |CS2_Pin|CS3_Pin|CONVERT_Pin;
  GPIO_InitStruct.Mode = GPIO_MODE_OUTPUT_PP;
  GPIO_InitStruct.Pull = GPIO_NOPULL;
  GPIO_InitStruct.Speed = GPIO_SPEED_FREQ_LOW;
  HAL_GPIO_Init(GPIOB, &GPIO_InitStruct);

  /*Configure GPIO pins : BOOT1_Pin PY5_Pin PY6_Pin INT8574_Pin */
  GPIO_InitStruct.Pin = BOOT1_Pin|PY5_Pin|PY6_Pin|INT8574_Pin;
  GPIO_InitStruct.Mode = GPIO_MODE_INPUT;
  GPIO_InitStruct.Pull = GPIO_NOPULL;
  HAL_GPIO_Init(GPIOB, &GPIO_InitStruct);

  /*Configure GPIO pins : D0_Pin D1_Pin D2_Pin D3_Pin
                           D4_Pin D5_Pin D6_Pin D7_Pin */
  GPIO_InitStruct.Pin = D0_Pin|D1_Pin|D2_Pin|D3_Pin
                          |D4_Pin|D5_Pin|D6_Pin|D7_Pin;
  GPIO_InitStruct.Mode = GPIO_MODE_INPUT;
  GPIO_InitStruct.Pull = GPIO_NOPULL;
  HAL_GPIO_Init(GPIOE, &GPIO_InitStruct);

  /*Configure GPIO pin : CLK_IN_Pin */
  GPIO_InitStruct.Pin = CLK_IN_Pin;
  GPIO_InitStruct.Mode = GPIO_MODE_AF_PP;
  GPIO_InitStruct.Pull = GPIO_NOPULL;
  GPIO_InitStruct.Speed = GPIO_SPEED_FREQ_LOW;
  GPIO_InitStruct.Alternate = GPIO_AF5_SPI2;
  HAL_GPIO_Init(CLK_IN_GPIO_Port, &GPIO_InitStruct);

  /*Configure GPIO pins : A0_Pin A1_Pin A2_Pin A3_Pin
                           LD4_Pin LD3_Pin LD5_Pin LD6_Pin
                           Audio_RST_Pin */
  GPIO_InitStruct.Pin = A0_Pin|A1_Pin|A2_Pin|A3_Pin
                          |LD4_Pin|LD3_Pin|LD5_Pin|LD6_Pin
                          |Audio_RST_Pin;
  GPIO_InitStruct.Mode = GPIO_MODE_OUTPUT_PP;
  GPIO_InitStruct.Pull = GPIO_NOPULL;
  GPIO_InitStruct.Speed = GPIO_SPEED_FREQ_LOW;
  HAL_GPIO_Init(GPIOD, &GPIO_InitStruct);

  /*Configure GPIO pins : I2S3_MCK_Pin I2S3_SCK_Pin I2S3_SD_Pin */
  GPIO_InitStruct.Pin = I2S3_MCK_Pin|I2S3_SCK_Pin|I2S3_SD_Pin;
  GPIO_InitStruct.Mode = GPIO_MODE_AF_PP;
  GPIO_InitStruct.Pull = GPIO_NOPULL;
  GPIO_InitStruct.Speed = GPIO_SPEED_FREQ_LOW;
  GPIO_InitStruct.Alternate = GPIO_AF6_SPI3;
  HAL_GPIO_Init(GPIOC, &GPIO_InitStruct);

  /*Configure GPIO pins : PX1_Pin PX0_Pin */
  GPIO_InitStruct.Pin = PX1_Pin|PX0_Pin;
  GPIO_InitStruct.Mode = GPIO_MODE_OUTPUT_PP;
  GPIO_InitStruct.Pull = GPIO_NOPULL;
  GPIO_InitStruct.Speed = GPIO_SPEED_FREQ_LOW;
  HAL_GPIO_Init(GPIOA, &GPIO_InitStruct);

  /*Configure GPIO pins : PY1_Pin PY2_Pin OTG_FS_OverCurrent_Pin PY3_Pin
                           PY4_Pin */
  GPIO_InitStruct.Pin = PY1_Pin|PY2_Pin|OTG_FS_OverCurrent_Pin|PY3_Pin
                          |PY4_Pin;
  GPIO_InitStruct.Mode = GPIO_MODE_INPUT;
  GPIO_InitStruct.Pull = GPIO_NOPULL;
  HAL_GPIO_Init(GPIOD, &GPIO_InitStruct);

  /*Configure GPIO pin : INT_KEY_Pin */
  GPIO_InitStruct.Pin = INT_KEY_Pin;
  GPIO_InitStruct.Mode = GPIO_MODE_IT_RISING;
  GPIO_InitStruct.Pull = GPIO_NOPULL;
  HAL_GPIO_Init(INT_KEY_GPIO_Port, &GPIO_InitStruct);

  /*Configure GPIO pin : MEMS_INT2_Pin */
  GPIO_InitStruct.Pin = MEMS_INT2_Pin;
  GPIO_InitStruct.Mode = GPIO_MODE_EVT_RISING;
  GPIO_InitStruct.Pull = GPIO_NOPULL;
  HAL_GPIO_Init(MEMS_INT2_GPIO_Port, &GPIO_InitStruct);

  /* EXTI interrupt init*/
  HAL_NVIC_SetPriority(EXTI9_5_IRQn, 0, 0);
  HAL_NVIC_EnableIRQ(EXTI9_5_IRQn);

}

void Error_Handler(void)
{
  while(1)
  {
  }
}

/************************ (C) COPYRIGHT STMicroelectronics *****END OF FILE****/
